VERSION ""

NS_ :

BS_:

BU_: Test HLU

BO_ 1280 NM: 3 Test
 SG_ HLU_Shutdown : 0|1@1+ (1,0) [0|0] ""  HLU

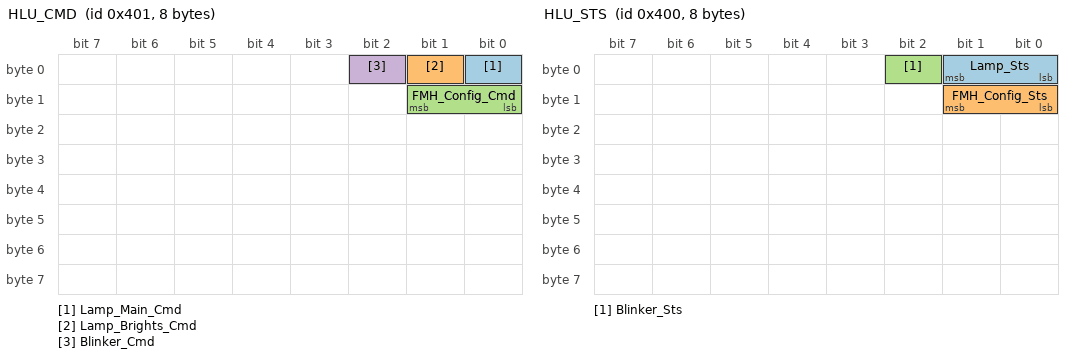
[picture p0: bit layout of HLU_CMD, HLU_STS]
BO_ 1025 HLU_CMD: 8 Test
 SG_ Lamp_Main_Cmd : 0|1@1+ (1,0) [0|0] ""  HLU
 SG_ Lamp_Brights_Cmd : 1|1@1+ (1,0) [0|0] ""  HLU
 SG_ FMH_Config_Cmd : 8|2@1+ (1,0) [0|0] ""  HLU
 SG_ Blinker_Cmd : 2|1@1+ (1,0) [0|0] ""  HLU

BO_ 1024 HLU_STS: 8 HLU
 SG_ Lamp_Sts : 0|2@1+ (1,0) [0|0] ""  Test
 SG_ FMH_Config_Sts : 8|2@1+ (1,0) [0|0] ""  Test
 SG_ Blinker_Sts : 2|1@1+ (1,0) [0|0] ""  Test

BA_DEF_  "BusType" STRING ;
BA_DEF_DEF_  "BusType" "CAN";
